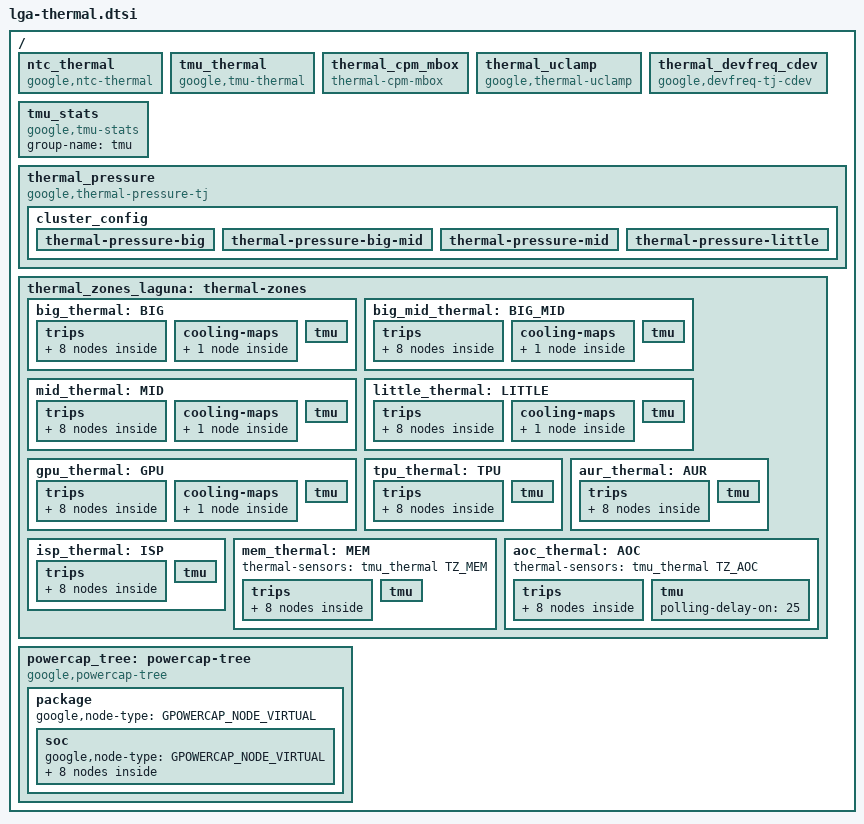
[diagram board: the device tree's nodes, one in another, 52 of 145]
// SPDX-License-Identifier: GPL-2.0-only
/*
 * Thermal device tree source
 *
 * Copyright 2023 Google LLC
 */
#include <dt-bindings/soc/google/google-thermal-def.h>

/ {
	ntc_thermal: ntc_thermal {
		compatible = "google,ntc-thermal";
		#thermal-sensor-cells = <1>;
		filter-spurious-samples;
		enable-hw-lpf;
	};

	tmu_thermal: tmu_thermal {
		compatible = "google,tmu-thermal";
		#thermal-sensor-cells = <1>;
	};

	thermal_cpm_mbox: thermal_cpm_mbox {
		compatible = "thermal-cpm-mbox";
		mba-dest-channel = <MBOX_DEST_CHAN_THERMAL_V2>;
		mboxes = <&goog_mba_cpm_iface>;
	};

	thermal_uclamp {
		compatible = "google,thermal-uclamp";
		google,cluster-cdev-map =
			< &hayes_0     HW_DT_CDEV_LIT >,
			< &hunter_0    HW_DT_CDEV_MID >,
			< &hunter_3    HW_DT_CDEV_BIG_MID >,
			< &hunterelp_0 HW_DT_CDEV_BIG >;
	};

	thermal_devfreq_cdev {
		compatible = "google,devfreq-tj-cdev";
		thermal-hw-cdev-id = <HW_DT_CDEV_GPU>;
		thermal-devfreq = <&gpu>;
	};

	tmu_stats: tmu_stats {
		compatible = "google,tmu-stats";
		group-name = "tmu";
	};

	thermal_pressure: thermal_pressure {
		compatible = "google,thermal-pressure-tj";
		group-name = "tmu";

		active-polling-delay-ms = <100>;
		passive-polling-delay-ms = <2500>;

		cluster_config {
			thermal-pressure-big {
				first-cpu = <&hunterelp_0>;
				cdev-id = <HW_DT_CDEV_BIG>;
			};
			thermal-pressure-big-mid {
				first-cpu = <&hunter_3>;
				cdev-id = <HW_DT_CDEV_BIG_MID>;
			};
			thermal-pressure-mid {
				first-cpu = <&hunter_0>;
				cdev-id = <HW_DT_CDEV_MID>;
			};
			thermal-pressure-little {
				first-cpu = <&hayes_0>;
				cdev-id = <HW_DT_CDEV_LIT>;
			};
		};
	};

	thermal_zones_laguna: thermal-zones {
		big_thermal: BIG {
			polling-delay = <0>;
			polling-delay-passive = <0>;
			thermal-sensors = <&tmu_thermal TZ_BIG>;

			trips {
				big_cold: big-cold {
					temperature = <20000>;
					hysteresis = <5000>;
					type = "active";
				};
				big_switch_on: big-switch-on {
					temperature = <80000>;
					hysteresis = <5000>;
					type = "active";
				};
				big_early_throttle: big-early_throttle {
					temperature = <85000>;
					hysteresis = <5000>;
					type = "active";
				};
				big_control_temp: big-control-temp {
					temperature = <95000>;
					hysteresis = <5000>;
					type = "passive";
				};
				big_alert1: big-alert1 {
					temperature = <97000>;
					hysteresis = <5000>;
					type = "active";
				};
				big_sw_max_effort: big-sw_max_effort {
					temperature = <107000>;
					hysteresis = <2000>;
					type = "active";
				};
				big_dfs: big-dfs {
					temperature = <102000>;
					hysteresis = <5000>;
					type = "active";
				};
				big_hot: big-hot {
					temperature = <115000>;
					hysteresis = <3000>;
					type = "hot";
				};
			};

			cooling-maps {
				map0 {
					trip = <&big_control_temp>;
					cooling-device =
						<&hunterelp_0 THERMAL_NO_LIMIT THERMAL_NO_LIMIT>;
				};
			};

			tmu {
				polling-delay-on = <5>;

				/* PI control param */
				pi-enable;
				k-po = <68>;
				k-pu = <68>;
				k-i = <50>;

				/* early throttle param */
				early-throttle-enable;
				early-throttle-k-p = <50>;

				/* gradual param */
				irq-gradual-gain = <2>;
				timer-gradual-gain = <1>;

				/* hardlimit param */
				hardlimit-enable;
				hardlimit-via-pid-enable;

				/* temp lut param */
				temp-lut-enable;

				/* Tj control offset - mC */
				junction-offset = <0 (-10000) (-10000) (-10000) 5000 0 0 0>;
			};
		};

		big_mid_thermal: BIG_MID {
			polling-delay = <0>;
			polling-delay-passive = <0>;
			thermal-sensors = <&tmu_thermal TZ_BIG_MID>;

			trips {
				big_mid_cold: big-mid-cold {
					temperature = <20000>;
					hysteresis = <5000>;
					type = "active";
				};
				big_mid_switch_on: big-mid-switch-on {
					temperature = <80000>;
					hysteresis = <5000>;
					type = "active";
				};
				big_mid_early_throttle: big-mid-early_throttle {
					temperature = <90000>;
					hysteresis = <5000>;
					type = "active";
				};
				big_mid_control_temp: big-mid-control-temp {
					temperature = <100000>;
					hysteresis = <5000>;
					type = "passive";
				};
				big_mid_alert1: big-mid-alert1 {
					temperature = <102000>;
					hysteresis = <5000>;
					type = "active";
				};
				big_mid_sw_max_effort: big-mid-sw_max_effort {
					temperature = <107000>;
					hysteresis = <2000>;
					type = "active";
				};
				big_mid_dfs: big-mid-dfs {
					temperature = <105000>;
					hysteresis = <5000>;
					type = "active";
				};
				big_mid_hot: big-mid-hot {
					temperature = <115000>;
					hysteresis = <3000>;
					type = "hot";
				};
			};

			cooling-maps {
				map0 {
					trip = <&big_mid_control_temp>;
					cooling-device =
						<&hunter_3 THERMAL_NO_LIMIT THERMAL_NO_LIMIT>;
				};
			};

			tmu {
				polling-delay-on = <5>;

				/* PI control param */
				pi-enable;
				k-po = <68>;
				k-pu = <68>;
				k-i = <50>;

				/* early throttle param */
				early-throttle-enable;
				early-throttle-k-p = <50>;

				/* gradual param */
				irq-gradual-gain = <2>;
				timer-gradual-gain = <1>;

				/* hardlimit param */
				hardlimit-enable;
				hardlimit-via-pid-enable;

				/* Tj control offset - mC */
				junction-offset = <0 (-10000) (-10000) (-10000) 5000 0 0 0>; // mC
			};
		};

		mid_thermal: MID {
			polling-delay = <0>;
			polling-delay-passive = <0>;
			thermal-sensors = <&tmu_thermal TZ_MID>;

			trips {
				mid_cold: mid-cold {
					temperature = <20000>;
					hysteresis = <5000>;
					type = "active";
				};
				mid_switch_on: mid-switch-on {
					temperature = <80000>;
					hysteresis = <5000>;
					type = "active";
				};
				mid_alert1: mid-alert1 {
					temperature = <90000>;
					hysteresis = <5000>;
					type = "active";
				};
				mid_control_temp: mid-control-temp {
					temperature = <100000>;
					hysteresis = <5000>;
					type = "passive";
				};
				mid_alert2: mid-alert2 {
					temperature = <102000>;
					hysteresis = <5000>;
					type = "active";
				};
				mid_sw_max_effort: mid-sw_max_effort {
					temperature = <107000>;
					hysteresis = <2000>;
					type = "active";
				};
				mid_dfs: mid-dfs {
					temperature = <105000>;
					hysteresis = <5000>;
					type = "active";
				};
				mid_hot: mid-hot {
					temperature = <115000>;
					hysteresis = <3000>;
					type = "hot";
				};
			};

			cooling-maps {
				map0 {
					trip = <&mid_control_temp>;
					cooling-device =
						<&hunter_0 THERMAL_NO_LIMIT THERMAL_NO_LIMIT>;
				};
			};

			tmu {
				polling-delay-on = <5>;

				/* PI control param */
				pi-enable;
				k-po = <36>;
				k-pu = <36>;
				k-i = <58>;

				/* early throttle param */
				early-throttle-enable;
				early-throttle-k-p = <50>;

				/* gradual param */
				irq-gradual-gain = <2>;
				timer-gradual-gain = <1>;

				/* hardlimit param */
				hardlimit-enable;
				hardlimit-via-pid-enable;

				/* Tj control offset - mC */
				junction-offset = <0 (-10000) (-10000) (-10000) 5000 0 0 0>; // mC
			};
		};

		little_thermal: LITTLE {
			polling-delay = <0>;
			polling-delay-passive = <0>;
			thermal-sensors = <&tmu_thermal TZ_LIT>;

			trips {
				little_cold: little-cold {
					temperature = <20000>;
					hysteresis = <5000>;
					type = "active";
				};
				little_switch_on: little-switch-on {
					temperature = <80000>;
					hysteresis = <5000>;
					type = "active";
				};
				little_alert1: little-alert1 {
					temperature = <97000>;
					hysteresis = <5000>;
					type = "active";
				};
				little_control_temp: little-control-temp {
					temperature = <100000>;
					hysteresis = <5000>;
					type = "passive";
				};
				little_alert2: little-alert2 {
					temperature = <102000>;
					hysteresis = <5000>;
					type = "active";
				};
				little_sw_max_effort: little-sw_max_effort {
					temperature = <107000>;
					hysteresis = <1000>;
					type = "active";
				};
				little_dfs: little-dfs {
					temperature = <105000>;
					hysteresis = <5000>;
					type = "active";
				};
				little_hot: little-hot {
					temperature = <115000>;
					hysteresis = <3000>;
					type = "hot";
				};
			};

			cooling-maps {
				map0 {
					trip = <&little_control_temp>;
					cooling-device =
						<&hayes_0 THERMAL_NO_LIMIT THERMAL_NO_LIMIT>;
				};
			};

			tmu {
				polling-delay-on = <5>;

				/* PI control param */
				pi-enable;
				k-po = <60>;
				k-pu = <60>;
				k-i = <20>;

				/* early throttle param */
				early-throttle-enable;
				early-throttle-k-p = <50>;

				/* gradual param */
				irq-gradual-gain = <2>;
				timer-gradual-gain = <1>;

				/* hardlimit param */
				hardlimit-via-pid-enable;

				/* Tj control offset - mC */
				junction-offset = <0 (-10000) (-10000) (-10000) 5000 0 0 0>; // mC
			};
		};

		gpu_thermal: GPU {
			polling-delay = <0>;
			polling-delay-passive = <0>;
			thermal-sensors = <&tmu_thermal TZ_GPU>;

			trips {
				gpu_cold: gpu-cold {
					temperature = <20000>;
					hysteresis = <5000>;
					type = "active";
				};
				gpu_switch_on: gpu-switch-on {
					temperature = <80000>;
					hysteresis = <5000>;
					type = "active";
				};
				gpu_alert1: gpu-alert1 {
					temperature = <95000>;
					hysteresis = <4000>;
					type = "passive";
				};
				gpu_control_temp: gpu-control-temp {
					temperature = <100000>;
					hysteresis = <5000>;
					type = "passive";
				};
				gpu_alert2: gpu-alert2 {
					temperature = <102000>;
					hysteresis = <5000>;
					type = "active";
				};
				gpu_sw_max_effort: gpu-sw_max_effort {
					temperature = <107000>;
					hysteresis = <2000>;
					type = "active";
				};
				gpu_dfs: gpu-dfs {
					temperature = <105000>;
					hysteresis = <5000>;
					type = "active";
				};
				gpu_hot: gpu-hot {
					temperature = <115000>;
					hysteresis = <3000>;
					type = "hot";
				};
			};

			cooling-maps {
				map0 {
					trip = <&gpu_control_temp>;
					cooling-device = <&gpu THERMAL_NO_LIMIT THERMAL_NO_LIMIT>;
				};
			};

			tmu {
				polling-delay-on = <25>;

				/* PI control param */
				pi-enable;
				k-po = <60>;
				k-pu = <60>;
				k-i = <50>;

				/* early throttle param */
				early-throttle-enable;
				early-throttle-k-p = <50>;

				/* gradual param */
				irq-gradual-gain = <2>;
				timer-gradual-gain = <1>;

				/* Tj control offset - mC */
				junction-offset = <0 (-10000) (-10000) (-10000) 0 0 0 0>; // mC
			};
		};

		tpu_thermal: TPU {
			polling-delay = <0>;
			polling-delay-passive = <0>;
			thermal-sensors = <&tmu_thermal TZ_TPU>;

			trips {
				tpu_cold: tpu-cold {
					temperature = <20000>;
					hysteresis = <5000>;
					type = "active";
				};
				tpu_switch_on: tpu-switch-on {
					temperature = <80000>;
					hysteresis = <5000>;
					type = "active";
				};
				tpu_alert1: tpu-alert1 {
					temperature = <95000>;
					hysteresis = <4000>;
					type = "passive";
				};
				tpu_control_temp: tpu-control-temp {
					temperature = <100000>;
					hysteresis = <5000>;
					type = "passive";
				};
				tpu_alert2: tpu-alert2 {
					temperature = <102000>;
					hysteresis = <5000>;
					type = "active";
				};
				tpu_sw_max_effort: tpu-sw-max-effort {
					temperature = <107000>;
					hysteresis = <2000>;
					type = "active";
				};
				tpu_dfs: tpu-dfs {
					temperature = <105000>;
					hysteresis = <5000>;
					type = "active";
				};
				tpu_hot: tpu-hot {
					temperature = <115000>;
					hysteresis = <3000>;
					type = "hot";
				};
			};

			tmu {
				polling-delay-on = <5>;

				/* PI control param */
				pi-enable;
				k-po = <60>;
				k-pu = <60>;
				k-i = <50>;

				/* early throttle param */

				/* gradual param */
				irq-gradual-gain = <2>;
				timer-gradual-gain = <1>;

				/* hardlimit param */
				hardlimit-enable;

				/* Tj control offset - mC */
				junction-offset = <0 (-10000) (-10000) (-10000) 0 0 0 0>; // mC
			};
		};

		aur_thermal: AUR {
			polling-delay = <0>;
			polling-delay-passive = <0>;
			thermal-sensors = <&tmu_thermal TZ_AUR>;

			trips {
				aur_cold: aur-cold {
					temperature = <20000>;
					hysteresis = <5000>;
					type = "active";
				};
				aur_switch_on: aur-switch-on {
					temperature = <80000>;
					hysteresis = <5000>;
					type = "active";
				};
				aur_alert1: aur-alert1 {
					temperature = <95000>;
					hysteresis = <4000>;
					type = "passive";
				};
				aur_control_temp: aur-control-temp {
					temperature = <100000>;
					hysteresis = <5000>;
					type = "passive";
				};
				aur_alert2: aur-alert2 {
					temperature = <102000>;
					hysteresis = <5000>;
					type = "active";
				};
				aur_sw_max_effort: aur-sw_max_effort {
					temperature = <107000>;
					hysteresis = <2000>;
					type = "active";
				};
				aur_dfs: aur-dfs {
					temperature = <105000>;
					hysteresis = <5000>;
					type = "active";
				};
				aur_hot: aur-hot {
					temperature = <115000>;
					hysteresis = <3000>;
					type = "hot";
				};
			};

			tmu {
				polling-delay-on = <25>;

				/* PI control param */
				/* early throttle param */
				/* hardlimit param */

				/* gradual param */
				irq-gradual-gain = <2>;
				timer-gradual-gain = <1>;


				/* Tj control offset - mC */
				junction-offset = <0 (-10000) (-10000) (-10000) 0 0 0 0>; // mC
			};

		};

		isp_thermal: ISP {
			polling-delay = <0>;
			polling-delay-passive = <0>;
			thermal-sensors = <&tmu_thermal TZ_ISP>;

			trips {
				isp_alert0: isp-alert0 {
					temperature = <20000>;
					hysteresis = <5000>;
					type = "active";
				};
				isp_alert1: isp-alert1 {
					temperature = <70000>;
					hysteresis = <5000>;
					type = "active";
				};
				isp_alert2: isp-alert2 {
					temperature = <90000>;
					hysteresis = <5000>;
					type = "passive";
				};
				isp_alert3: isp-alert3 {
					temperature = <95000>;
					hysteresis = <4000>;
					type = "passive";
				};
				isp_alert4: isp-alert4 {
					temperature = <98000>;
					hysteresis = <98000>;
					type = "active";
				};
				isp_alert5: isp-alert5 {
					temperature = <102000>;
					hysteresis = <102000>;
					type = "active";
				};
				isp_alert6: isp-alert6 {
					temperature = <105000>;
					hysteresis = <105000>;
					type = "active";
				};
				isp_hot: isp-hot {
					temperature = <115000>;
					hysteresis = <3000>;
					type = "hot";
				};
			};

			tmu {
				polling-delay-on = <25>;

				/* PI control param */
				/* early throttle param */
				/* hardlimit param */

				/* gradual param */
				irq-gradual-gain = <2>;
				timer-gradual-gain = <1>;

				/* Tj control offset - mC */
			};
		};

		mem_thermal: MEM {
			thermal-sensors = <&tmu_thermal TZ_MEM>;

			trips {
				mem_alert0: mem-alert0 {
					temperature = <20000>;
					hysteresis = <5000>;
					type = "passive";
				};
				mem_alert1: mem-alert1 {
					temperature = <70000>;
					hysteresis = <5000>;
					type = "passive";
				};
				mem_alert2: mem-alert2 {
					temperature = <90000>;
					hysteresis = <5000>;
					type = "passive";
				};
				mem_alert3: mem-alert3 {
					temperature = <95000>;
					hysteresis = <4000>;
					type = "passive";
				};
				mem_alert4: mem-alert4 {
					temperature = <98000>;
					hysteresis = <98000>;
					type = "passive";
				};
				mem_alert5: mem-alert5 {
					temperature = <102000>;
					hysteresis = <102000>;
					type = "passive";
				};
				mem_alert6: mem-alert6 {
					temperature = <105000>;
					hysteresis = <105000>;
					type = "passive";
				};
				mem_hot: mem-hot {
					temperature = <115000>;
					hysteresis = <3000>;
					type = "hot";
				};
			};

			tmu {
				polling-delay-on = <25>;

				/* PI control param */
				/* early throttle param */

				/* gradual param */
				irq-gradual-gain = <2>;
				timer-gradual-gain = <1>;

				/* hardlimit param */

				/* Tj control offset - mC */
			};
		};

		aoc_thermal: AOC {
			thermal-sensors = <&tmu_thermal TZ_AOC>;

			trips {
				aoc_cold: aoc-cold {
					temperature = <12000>;
					hysteresis = <5000>;
					type = "active";
				};
				aoc_alert1: aoc-alert1 {
					temperature = <70000>;
					hysteresis = <5000>;
					type = "passive";
				};
				aoc_alert2: aoc-alert2 {
					temperature = <90000>;
					hysteresis = <5000>;
					type = "passive";
				};
				aoc_alert3: aoc-alert3 {
					temperature = <95000>;
					hysteresis = <4000>;
					type = "passive";
				};
				aoc_alert4: aoc-alert4 {
					temperature = <98000>;
					hysteresis = <98000>;
					type = "passive";
				};
				aoc_alert5: aoc-alert5 {
					temperature = <102000>;
					hysteresis = <102000>;
					type = "passive";
				};
				aoc_alert6: aoc-alert6 {
					temperature = <105000>;
					hysteresis = <105000>;
					type = "passive";
				};
				aoc_hot: aoc-hot {
					temperature = <115000>;
					hysteresis = <3000>;
					type = "hot";
				};
			};

			tmu {
				polling-delay-on = <25>;

				/* PI control param */
				/* early throttle param */
				/* gradual param */
				/* hardlimit param */

				/* Tj control offset - mC */
			};
		};
	};

	powercap_tree: powercap-tree {
		compatible = "google,powercap-tree";

		package {
			google,node-type = <GPOWERCAP_NODE_VIRTUAL>;

			soc {
				google,node-type = <GPOWERCAP_NODE_VIRTUAL>;

				little-cluster {
					google,node-type = <GPOWERCAP_NODE_CPU>;
					google,device-phandle = <&hayes_0>;
					google,cdev-id = <HW_DT_CDEV_LIT>;
				};

				mid-cluster {
					google,node-type = <GPOWERCAP_NODE_CPU>;
					google,device-phandle = <&hunter_0>;
					google,cdev-id = <HW_DT_CDEV_MID>;
				};

				big_and_big_mid {
					google,node-type = <GPOWERCAP_NODE_VIRTUAL_VOLTAGE>;

					big-mid-cluster {
						google,node-type = <GPOWERCAP_NODE_CPU>;
						google,device-phandle = <&hunter_3>;
						google,cdev-id = <HW_DT_CDEV_BIG_MID>;
					};

					big-cluster {
						google,node-type = <GPOWERCAP_NODE_CPU>;
						google,device-phandle = <&hunterelp_0>;
						google,cdev-id = <HW_DT_CDEV_BIG>;
					};

				};

				gpu {
					google,node-type = <GPOWERCAP_NODE_DEVFREQ>;
					google,device-phandle = <&gpu>;
					google,cdev-id = <HW_DT_CDEV_GPU>;
				};

				aur {
					google,node-type = <GPOWERCAP_NODE_DEVFREQ>;
					google,device-phandle = <&gxp>;
					google,cdev-id = <HW_DT_CDEV_AUR>;
				};

				tpu {
					google,node-type = <GPOWERCAP_NODE_DEVFREQ>;
					google,device-phandle = <&edgetpu>;
					google,cdev-id = <HW_DT_CDEV_TPU>;
				};
			};
		};
	};
};
